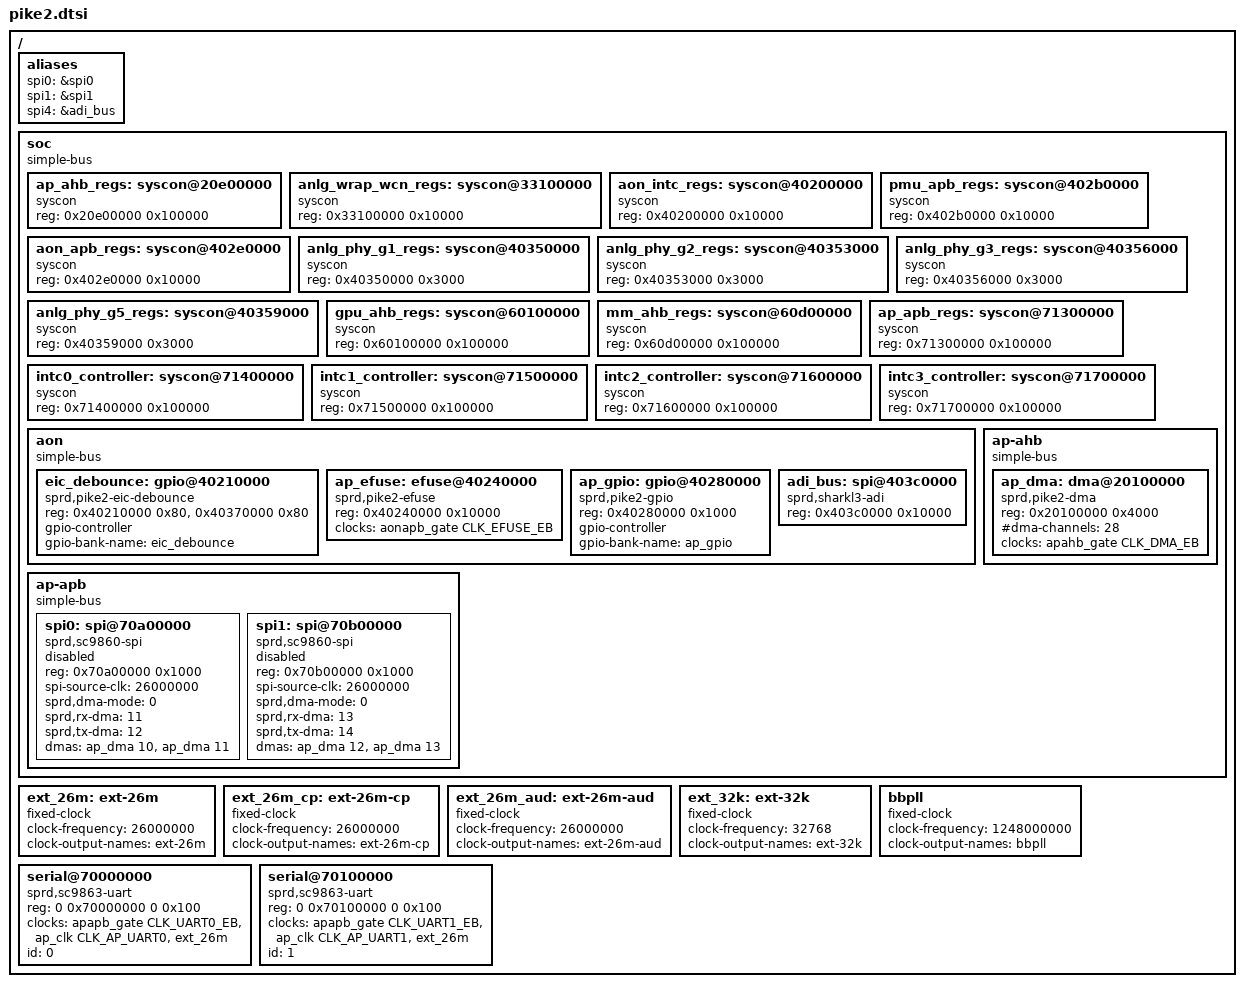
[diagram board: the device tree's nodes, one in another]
/*
 * Spreadtrum pike2 platform DTS file
 *
 * Copyright (C) 2019, Spreadtrum Communications Inc.
 *
 * This file is licensed under a dual GPLv2 or X11 license.
 */

#include <dt-bindings/gpio/gpio.h>
#include <dt-bindings/clock/sprd,sc7731e-clk.h>

/ {
	aliases {
		spi0 = &spi0;
		spi1 = &spi1;
		spi4 = &adi_bus;
	};

	soc: soc {
		compatible = "simple-bus";
		ranges;

		ap_ahb_regs: syscon@20e00000 {
			compatible = "syscon";
			#syscon-cells = <2>;
			reg = <0x20e00000 0x100000>;
		};

		anlg_wrap_wcn_regs: syscon@33100000 {
			compatible = "syscon";
			#syscon-cells = <2>;
			reg = <0x33100000 0x10000>;
		};

		aon_intc_regs: syscon@40200000 {
			compatible = "syscon";
			#syscon-cells = <2>;
			reg = <0x40200000 0x10000>;
		};

		pmu_apb_regs: syscon@402b0000 {
			compatible = "syscon";
			#syscon-cells = <2>;
			reg = <0x402b0000 0x10000>;
		};

		aon_apb_regs: syscon@402e0000 {
			compatible = "syscon";
			#syscon-cells = <2>;
			reg = <0x402e0000 0x10000>;
		};

		anlg_phy_g1_regs: syscon@40350000 {
			compatible = "syscon";
			#syscon-cells = <2>;
			reg = <0x40350000 0x3000>;
		};

		anlg_phy_g2_regs: syscon@40353000 {
			compatible = "syscon";
			#syscon-cells = <2>;
			reg = <0x40353000 0x3000>;
		};

		anlg_phy_g3_regs: syscon@40356000 {
			compatible = "syscon";
			#syscon-cells = <2>;
			reg = <0x40356000 0x3000>;
		};

		anlg_phy_g5_regs: syscon@40359000 {
			compatible = "syscon";
			#syscon-cells = <2>;
			reg = <0x40359000 0x3000>;
		};

		gpu_ahb_regs: syscon@60100000 {
			compatible = "syscon";
			#syscon-cells = <2>;
			reg = <0x60100000 0x100000>;
		};

		mm_ahb_regs: syscon@60d00000 {
			compatible = "syscon";
			#syscon-cells = <2>;
			reg = <0x60d00000 0x100000>;
		};

		ap_apb_regs: syscon@71300000 {
			compatible = "syscon";
			#syscon-cells = <2>;
			reg = <0x71300000 0x100000>;
		};

		intc0_controller: syscon@71400000 {
			compatible = "syscon";
			#syscon-cells = <2>;
			reg = <0x71400000 0x100000>;
		};

		intc1_controller: syscon@71500000 {
			compatible = "syscon";
			#syscon-cells = <2>;
			reg = <0x71500000 0x100000>;
		};

		intc2_controller: syscon@71600000 {
			compatible = "syscon";
			#syscon-cells = <2>;
			reg = <0x71600000 0x100000>;
		};

		intc3_controller: syscon@71700000 {
			compatible = "syscon";
			#syscon-cells = <2>;
			reg = <0x71700000 0x100000>;
		};
		aon {
			compatible = "simple-bus";
			#address-cells = <1>;
			#size-cells = <1>;
			ranges;

			eic_debounce: gpio@40210000 {
				compatible = "sprd,pike2-eic-debounce";
				reg = <0x40210000 0x80>,
				      <0x40370000 0x80>;
				gpio-controller;
				gpio-bank-name = "eic_debounce";
				#gpio-cells = <2>;
			};

			ap_efuse: efuse@40240000 {
				compatible = "sprd,pike2-efuse";
				reg = <0x40240000 0x10000>;
				clock-names = "enable";
				clocks = <&aonapb_gate CLK_EFUSE_EB>;
			};

			ap_gpio: gpio@40280000 {
				compatible = "sprd,pike2-gpio";
				reg = <0x40280000 0x1000>;
				gpio-controller;
				gpio-bank-name = "ap_gpio";
				#gpio-cells = <2>;
			};

			adi_bus: spi@403c0000 {
				compatible = "sprd,sharkl3-adi", "sprd,pike2-adi";
				reg = <0x403c0000 0x10000>;
				#address-cells = <1>;
				#size-cells = <0>;
			};
		};
		ap-apb {
			compatible = "simple-bus";
			#address-cells = <1>;
			#size-cells = <1>;
			ranges;

			spi0: spi@70a00000{
				compatible = "sprd,sc9860-spi",
						"sprd,pike2-spi";
				reg = <0x70a00000 0x1000>;
				spi-source-clk = <26000000>;
				sprd,dma-mode = <0>;
				sprd,rx-dma = <11>;
				sprd,tx-dma = <12>;
				dmas = <&ap_dma 10>, <&ap_dma 11>;
				dma-names = "rx-chn", "tx-chn";
				#address-cells = <1>;
				#size-cells = <0>;
				status = "disabled";
			};

			spi1: spi@70b00000{
				compatible = "sprd,sc9860-spi",
						"sprd,pike2-spi";
				reg = <0x70b00000 0x1000>;
				spi-source-clk = <26000000>;
				sprd,dma-mode = <0>;
				sprd,rx-dma = <13>;
				sprd,tx-dma = <14>;
				dmas = <&ap_dma 12>, <&ap_dma 13>;
				dma-names = "rx-chn", "tx-chn";
				#address-cells = <1>;
				#size-cells = <0>;
				status = "disabled";
			};
		};

		ap-ahb {
			compatible = "simple-bus";
			#address-cells = <1>;
			#size-cells = <1>;
			ranges;

			ap_dma: dma@20100000 {
				compatible = "sprd,pike2-dma";
				reg = <0x20100000 0x4000>;
				#dma-cells = <1>;
				#dma-channels = <28>;
				clock-names = "enable";
				clocks = <&apahb_gate CLK_DMA_EB>;
			};
		};
	};

	ext_26m: ext-26m {
		compatible = "fixed-clock";
		#clock-cells = <0>;
		clock-frequency = <26000000>;
		clock-output-names = "ext-26m";
	};

	ext_26m_cp: ext-26m-cp {
		compatible = "fixed-clock";
		#clock-cells = <0>;
		clock-frequency = <26000000>;
		clock-output-names = "ext-26m-cp";
	};

	ext_26m_aud: ext-26m-aud {
		compatible = "fixed-clock";
		#clock-cells = <0>;
		clock-frequency = <26000000>;
		clock-output-names = "ext-26m-aud";
	};

	ext_32k: ext-32k {
		compatible = "fixed-clock";
		#clock-cells = <0>;
		clock-frequency = <32768>;
		clock-output-names = "ext-32k";
	};

	bbpll: bbpll {
		compatible = "fixed-clock";
		#clock-cells = <0>;
		clock-frequency = <1248000000>;
		clock-output-names = "bbpll";
	};

	serial@70000000 {
		compatible = "sprd,sc9863-uart";
		reg = <0 0x70000000 0 0x100>;
		clock-names = "enable", "uart", "source";
		clocks = <&apapb_gate CLK_UART0_EB>,
		         <&ap_clk CLK_AP_UART0>,
		         <&ext_26m>;
		id = <0>;
	};

	serial@70100000 {
	        compatible = "sprd,sc9863-uart";
	        reg = <0 0x70100000 0 0x100>;
	        clock-names = "enable", "uart", "source";
	        clocks = <&apapb_gate CLK_UART1_EB>,
	                 <&ap_clk CLK_AP_UART1>,
	                 <&ext_26m>;
	        id = <1>;
	};


};
